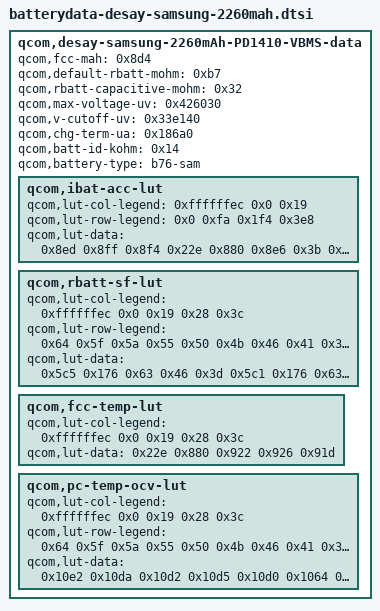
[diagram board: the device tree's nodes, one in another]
/* Copyright (c) 2018, The Linux Foundation. All rights reserved.
*
* This program is free software; you can redistribute it and/or modify
* it under the terms of the GNU General Public License version 2 and
* only version 2 as published by the Free Software Foundation.
*
* This program is distributed in the hope that it will be useful,
* but WITHOUT ANY WARRANTY; without even the implied warranty of
* MERCHANTABILITY or FITNESS FOR A PARTICULAR PURPOSE.  See the
* GNU General Public License for more details.
*/

qcom,desay-samsung-2260mAh-PD1410-VBMS-data {
	qcom,fcc-mah = <0x8d4>;
	qcom,default-rbatt-mohm = <0xb7>;
	qcom,rbatt-capacitive-mohm = <0x32>;
	qcom,max-voltage-uv = <0x426030>;
	qcom,v-cutoff-uv = <0x33e140>;
	qcom,chg-term-ua = <0x186a0>;
	qcom,batt-id-kohm = <0x14>;
	qcom,battery-type = "b76-sam";

	qcom,ibat-acc-lut {
		qcom,lut-col-legend = <0xffffffec 0x0 0x19>;
		qcom,lut-row-legend = <0x0 0xfa 0x1f4 0x3e8>;
		qcom,lut-data = <0x8ed 0x8ff 0x8f4 0x22e 0x880 0x8e6 0x3b 0x6fe 0x8d6 0x6 0x404 0x8a6>;
	};

	qcom,rbatt-sf-lut {
		qcom,lut-col-legend = <0xffffffec 0x0 0x19 0x28 0x3c>;
		qcom,lut-row-legend = <0x64 0x5f 0x5a 0x55 0x50 0x4b 0x46 0x41 0x3c 0x37 0x32 0x2d 0x28 0x23 0x1e 0x19 0x14 0x10 0xd 0xb 0xa 0x9 0x8 0x7 0x6 0x5 0x4 0x3 0x2 0x1 0x0>;
		qcom,lut-data = <0x5c5 0x176 0x63 0x46 0x3d 0x5c1 0x176 0x63 0x46 0x3d 0x559 0x174 0x65 0x48 0x3e 0x511 0x174 0x67 0x4a 0x3f 0x4ae 0x16f 0x6b 0x4d 0x42 0x48b 0x162 0x72 0x50 0x43 0x476 0x13a 0x72 0x53 0x46 0x478 0x13d 0x75 0x57 0x48 0x48c 0x13d 0x67 0x57 0x4a 0x4ac 0x13b 0x5f 0x4b 0x42 0x4d6 0x13c 0x5d 0x48 0x3e 0x505 0x13b 0x5f 0x49 0x3f 0x536 0x140 0x62 0x4b 0x42 0x576 0x14f 0x63 0x4d 0x44 0x5d4 0x166 0x65 0x4d 0x43 0x64a 0x188 0x65 0x4a 0x40 0x6ea 0x1b7 0x65 0x49 0x40 0x780 0x1de 0x64 0x49 0x40 0x6a2 0x1bd 0x5e 0x46 0x3e 0x70c 0x1d1 0x60 0x48 0x3f 0x78c 0x1dc 0x62 0x49 0x40 0x81d 0x1e9 0x65 0x4b 0x42 0x8c3 0x1f9 0x68 0x4c 0x43 0x98d 0x20a 0x6c 0x4e 0x45 0xa89 0x21a 0x6f 0x50 0x46 0xbc6 0x22d 0x6d 0x4d 0x40 0xd6a 0x243 0x6b 0x4b 0x40 0xfe8 0x265 0x6f 0x4e 0x43 0x1456 0x295 0x79 0x54 0x4a 0x247d 0x39c 0xdd 0x73 0x6b 0x247d 0x39c 0xdd 0x73 0x6b>;
	};

	qcom,fcc-temp-lut {
		qcom,lut-col-legend = <0xffffffec 0x0 0x19 0x28 0x3c>;
		qcom,lut-data = <0x22e 0x880 0x922 0x926 0x91d>;
	};

	qcom,pc-temp-ocv-lut {
		qcom,lut-col-legend = <0xffffffec 0x0 0x19 0x28 0x3c>;
		qcom,lut-row-legend = <0x64 0x5f 0x5a 0x55 0x50 0x4b 0x46 0x41 0x3c 0x37 0x32 0x2d 0x28 0x23 0x1e 0x19 0x14 0x10 0xd 0xb 0xa 0x9 0x8 0x7 0x6 0x5 0x4 0x3 0x2 0x1 0x0>;
		qcom,lut-data = <0x10e2 0x10da 0x10d2 0x10d5 0x10d0 0x1064 0x108d 0x1095 0x1097 0x1094 0x1018 0x1054 0x105e 0x1060 0x105c 0xfde 0x1020 0x102a 0x102c 0x1028 0xf86 0xfef 0xff8 0xff9 0xff6 0xf52 0xfb6 0xfcc 0xfca 0xfc6 0xf25 0xf6e 0xf92 0xf9b 0xf9b 0xf04 0xf4a 0xf6e 0xf76 0xf74 0xeee 0xf2a 0xf41 0xf4c 0xf4c 0xeda 0xf0c 0xf1a 0xf1f 0xf1e 0xec8 0xef0 0xefe 0xf00 0xeff 0xeb6 0xed6 0xee8 0xeea 0xee8 0xea5 0xec0 0xed6 0xed6 0xed6 0xe94 0xeae 0xec6 0xec6 0xec6 0xe84 0xe9e 0xeb8 0xeb8 0xeb2 0xe72 0xe92 0xeaa 0xea6 0xe9a 0xe5e 0xe88 0xe98 0xe93 0xe86 0xe4a 0xe7f 0xe82 0xe7c 0xe6e 0xe38 0xe76 0xe6c 0xe65 0xe59 0xe29 0xe6f 0xe68 0xe61 0xe56 0xe1e 0xe6a 0xe66 0xe60 0xe55 0xe14 0xe64 0xe66 0xe60 0xe54 0xe06 0xe5e 0xe64 0xe5e 0xe52 0xdf8 0xe56 0xe60 0xe5b 0xe50 0xde5 0xe48 0xe58 0xe53 0xe47 0xdce 0xe31 0xe40 0xe3a 0xe27 0xdaf 0xe0d 0xe11 0xe0c 0xdf6 0xd86 0xdd7 0xdd1 0xdce 0xdb9 0xd44 0xd85 0xd78 0xd79 0xd66 0xcd0 0xcfa 0xcf4 0xcf8 0xce6 0xbb8 0xbb8 0xbb8 0xbb8 0xbb8>;
	};
};

